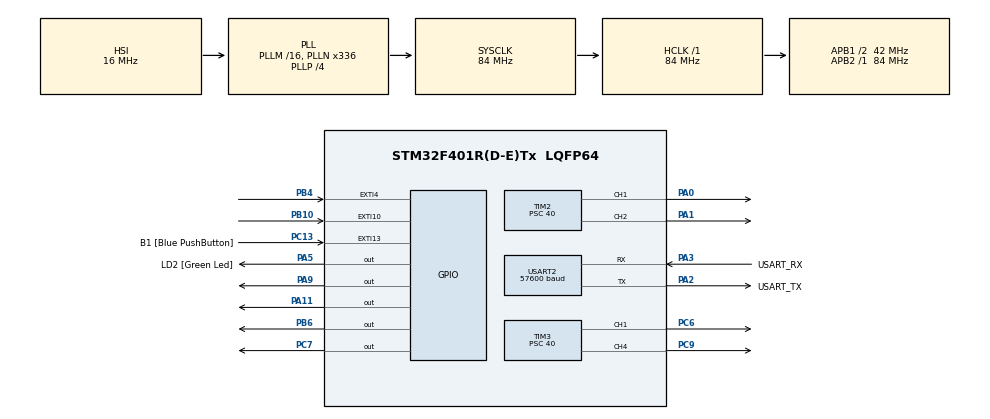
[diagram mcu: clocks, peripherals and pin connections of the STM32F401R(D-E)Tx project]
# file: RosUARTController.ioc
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Dma.Request0=USART2_RX
Dma.Request1=USART2_TX
Dma.USART2_RX.0.Direction=DMA_PERIPH_TO_MEMORY
Dma.USART2_RX.0.FIFOMode=DMA_FIFOMODE_DISABLE
Dma.USART2_RX.0.Instance=DMA1_Stream5
Dma.USART2_RX.0.MemDataAlignment=DMA_MDATAALIGN_BYTE
Dma.USART2_RX.0.MemInc=DMA_MINC_ENABLE
Dma.USART2_RX.0.Mode=DMA_NORMAL
Dma.USART2_RX.0.PeriphDataAlignment=DMA_PDATAALIGN_BYTE
Dma.USART2_RX.0.PeriphInc=DMA_PINC_DISABLE
Dma.USART2_RX.0.Priority=DMA_PRIORITY_HIGH
Dma.USART2_TX.1.Direction=DMA_MEMORY_TO_PERIPH
Dma.USART2_TX.1.FIFOMode=DMA_FIFOMODE_DISABLE
Dma.USART2_TX.1.Instance=DMA1_Stream6
Dma.USART2_TX.1.MemDataAlignment=DMA_MDATAALIGN_BYTE
Dma.USART2_TX.1.MemInc=DMA_MINC_ENABLE
Dma.USART2_TX.1.Mode=DMA_NORMAL
Dma.USART2_TX.1.PeriphDataAlignment=DMA_PDATAALIGN_BYTE
Dma.USART2_TX.1.PeriphInc=DMA_PINC_DISABLE
Dma.USART2_TX.1.Priority=DMA_PRIORITY_HIGH
FREERTOS.Tasks01=defaultTask,0,128,StartDefaultTask,Default,NULL
Mcu.Family=STM32F4
Mcu.Name=STM32F401R(D-E)Tx
Mcu.Package=LQFP64
NVIC.DMA1_Stream5_IRQn=true\:5\:0\:false\:false\:true\:true\:false\:true
NVIC.DMA1_Stream6_IRQn=true\:5\:0\:false\:false\:true\:true\:false\:true
NVIC.EXTI15_10_IRQn=true\:5\:0\:false\:false\:true\:true\:true\:true
NVIC.EXTI4_IRQn=true\:5\:0\:false\:false\:true\:true\:true\:true
NVIC.PriorityGroup=NVIC_PRIORITYGROUP_4
NVIC.TIM1_UP_TIM10_IRQn=true\:0\:0\:false\:false\:true\:false\:false\:true
NVIC.TimeBase=TIM1_UP_TIM10_IRQn
NVIC.TimeBaseIP=TIM1
NVIC.USART2_IRQn=true\:5\:0\:false\:false\:true\:true\:true\:true
PA0-WKUP.Signal=S_TIM2_CH1_ETR
PA1.Signal=S_TIM2_CH2
PA11.Signal=GPIO_Output
PA13.GPIO_Label=TMS
PA13.Mode=Serial_Wire
PA13.Signal=SYS_JTMS-SWDIO
PA14.GPIO_Label=TCK
PA14.Mode=Serial_Wire
PA14.Signal=SYS_JTCK-SWCLK
PA2.GPIO_Label=USART_TX
PA2.GPIO_Mode=GPIO_MODE_AF_PP
PA2.GPIO_PuPd=GPIO_NOPULL
PA2.GPIO_Speed=GPIO_SPEED_FREQ_LOW
PA2.Mode=Asynchronous
PA2.Signal=USART2_TX
PA3.GPIO_Label=USART_RX
PA3.GPIO_Mode=GPIO_MODE_AF_PP
PA3.GPIO_PuPd=GPIO_NOPULL
PA3.GPIO_Speed=GPIO_SPEED_FREQ_LOW
PA3.Mode=Asynchronous
PA3.Signal=USART2_RX
PA5.GPIO_Label=LD2 [Green Led]
PA5.GPIO_Mode=GPIO_MODE_OUTPUT_PP
PA5.GPIO_PuPd=GPIO_NOPULL
PA5.GPIO_Speed=GPIO_SPEED_FREQ_LOW
PA5.Signal=GPIO_Output
PA9.Signal=GPIO_Output
PB10.GPIO_ModeDefaultEXTI=GPIO_MODE_IT_RISING_FALLING
PB10.Signal=GPXTI10
PB3.GPIO_Label=SWO
PB3.Signal=SYS_JTDO-SWO
PB4.GPIO_ModeDefaultEXTI=GPIO_MODE_IT_RISING_FALLING
PB4.Signal=GPXTI4
PB6.Signal=GPIO_Output
PC13-ANTI_TAMP.GPIO_Label=B1 [Blue PushButton]
PC13-ANTI_TAMP.GPIO_ModeDefaultEXTI=GPIO_MODE_IT_FALLING
PC13-ANTI_TAMP.GPIO_PuPd=GPIO_NOPULL
PC13-ANTI_TAMP.Signal=GPXTI13
PC14-OSC32_IN.Mode=LSE-External-Oscillator
PC14-OSC32_IN.Signal=RCC_OSC32_IN
PC15-OSC32_OUT.Mode=LSE-External-Oscillator
PC15-OSC32_OUT.Signal=RCC_OSC32_OUT
PC6.Signal=S_TIM3_CH1
PC7.Signal=GPIO_Output
PC9.Signal=S_TIM3_CH4
PH0\ -\ OSC_IN.Mode=HSE-External-Oscillator
PH0\ -\ OSC_IN.Signal=RCC_OSC_IN
PH1\ -\ OSC_OUT.Mode=HSE-External-Oscillator
PH1\ -\ OSC_OUT.Signal=RCC_OSC_OUT
ProjectManager.HeapSize=0x200
ProjectManager.StackSize=0x400
ProjectManager.TargetToolchain=STM32CubeIDE
RCC.48MHZClocksFreq_Value=48000000
RCC.AHBFreq_Value=84000000
RCC.APB1CLKDivider=RCC_HCLK_DIV2
RCC.APB1Freq_Value=42000000
RCC.APB1TimFreq_Value=84000000
RCC.APB2Freq_Value=84000000
RCC.APB2TimFreq_Value=84000000
RCC.CortexFreq_Value=84000000
RCC.HCLKFreq_Value=84000000
RCC.HSE_VALUE=8000000
RCC.HSI_VALUE=16000000
RCC.PLLN=336
RCC.PLLP=RCC_PLLP_DIV4
RCC.PLLQ=7
RCC.SYSCLKFreq_VALUE=84000000
RCC.SYSCLKSource=RCC_SYSCLKSOURCE_PLLCLK
RCC.VCOOutputFreq_Value=336000000
SH.S_TIM2_CH1_ETR.0=TIM2_CH1,PWM Generation1 CH1
SH.S_TIM2_CH2.0=TIM2_CH2,PWM Generation2 CH2
SH.S_TIM3_CH1.0=TIM3_CH1,PWM Generation1 CH1
SH.S_TIM3_CH4.0=TIM3_CH4,PWM Generation4 CH4
TIM2.Channel-PWM\ Generation1\ CH1=TIM_CHANNEL_1
TIM2.Channel-PWM\ Generation2\ CH2=TIM_CHANNEL_2
TIM2.Period=256
TIM2.Prescaler=40
TIM3.Channel-PWM\ Generation1\ CH1=TIM_CHANNEL_1
TIM3.Channel-PWM\ Generation4\ CH4=TIM_CHANNEL_4
TIM3.Period=256
TIM3.Prescaler=40
USART2.BaudRate=57600
USART2.VirtualMode=VM_ASYNC
VP_FREERTOS_VS_CMSIS_V1.Mode=CMSIS_V1
VP_SYS_VS_tim1.Mode=TIM1
VP_TIM2_VS_ClockSourceINT.Mode=Internal
VP_TIM3_VS_ClockSourceINT.Mode=Internal
board=NUCLEO-F401RE

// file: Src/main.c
/* USER CODE BEGIN Header */
/**
  ******************************************************************************
  * @file           : main.c
  * @brief          : Main program body
  ******************************************************************************
  * @attention
  *
  * <h2><center>&copy; Copyright (c) 2019 STMicroelectronics.
  * All rights reserved.</center></h2>
  *
  * This software component is licensed by ST under BSD 3-Clause license,
  * the "License"; You may not use this file except in compliance with the
  * License. You may obtain a copy of the License at:
  *                        opensource.org/licenses/BSD-3-Clause
  *
  ******************************************************************************
  */
/* USER CODE END Header */

#include "main.h"
#include "cmsis_os.h"

TIM_HandleTypeDef htim2;
TIM_HandleTypeDef htim3;

UART_HandleTypeDef huart2;
DMA_HandleTypeDef hdma_usart2_rx;
DMA_HandleTypeDef hdma_usart2_tx;

osThreadId defaultTaskHandle;

void SystemClock_Config(void);
static void MX_GPIO_Init(void);
static void MX_DMA_Init(void);
static void MX_USART2_UART_Init(void);
static void MX_TIM2_Init(void);
static void MX_TIM3_Init(void);
void StartDefaultTask(void const * argument);

int main(void)
{

  /* MCU Configuration--------------------------------------------------------*/

  /* Reset of all peripherals, Initializes the Flash interface and the Systick. */
  HAL_Init();

  /* Configure the system clock */
  SystemClock_Config();

  /* Initialize all configured peripherals */
  MX_GPIO_Init();
  MX_DMA_Init();
  MX_USART2_UART_Init();
  MX_TIM2_Init();
  MX_TIM3_Init();
  /* USER CODE BEGIN 2 */
    setup(&huart2, &htim2, &htim3);
  /* USER CODE END 2 */

  /* Create the thread(s) */
  /* definition and creation of defaultTask */
  osThreadDef(defaultTask, StartDefaultTask, osPriorityNormal, 0, 128);
  defaultTaskHandle = osThreadCreate(osThread(defaultTask), NULL);

  /* Start scheduler */
  osKernelStart();

  /* We should never get here as control is now taken by the scheduler */

  /* Infinite loop */
  while (1)
  {

  }
}

void SystemClock_Config(void)
{
  RCC_OscInitTypeDef RCC_OscInitStruct = {0};
  RCC_ClkInitTypeDef RCC_ClkInitStruct = {0};

  /** Configure the main internal regulator output voltage
  */
  __HAL_RCC_PWR_CLK_ENABLE();
  __HAL_PWR_VOLTAGESCALING_CONFIG(PWR_REGULATOR_VOLTAGE_SCALE2);
  /** Initializes the CPU, AHB and APB busses clocks
  */
  RCC_OscInitStruct.OscillatorType = RCC_OSCILLATORTYPE_HSI;
  RCC_OscInitStruct.HSIState = RCC_HSI_ON;
  RCC_OscInitStruct.HSICalibrationValue = RCC_HSICALIBRATION_DEFAULT;
  RCC_OscInitStruct.PLL.PLLState = RCC_PLL_ON;
  RCC_OscInitStruct.PLL.PLLSource = RCC_PLLSOURCE_HSI;
  RCC_OscInitStruct.PLL.PLLM = 16;
  RCC_OscInitStruct.PLL.PLLN = 336;
  RCC_OscInitStruct.PLL.PLLP = RCC_PLLP_DIV4;
  RCC_OscInitStruct.PLL.PLLQ = 7;
  if (HAL_RCC_OscConfig(&RCC_OscInitStruct) != HAL_OK)
  {
    Error_Handler();
  }
  /** Initializes the CPU, AHB and APB busses clocks
  */
  RCC_ClkInitStruct.ClockType = RCC_CLOCKTYPE_HCLK|RCC_CLOCKTYPE_SYSCLK
                              |RCC_CLOCKTYPE_PCLK1|RCC_CLOCKTYPE_PCLK2;
  RCC_ClkInitStruct.SYSCLKSource = RCC_SYSCLKSOURCE_PLLCLK;
  RCC_ClkInitStruct.AHBCLKDivider = RCC_SYSCLK_DIV1;
  RCC_ClkInitStruct.APB1CLKDivider = RCC_HCLK_DIV2;
  RCC_ClkInitStruct.APB2CLKDivider = RCC_HCLK_DIV1;

  if (HAL_RCC_ClockConfig(&RCC_ClkInitStruct, FLASH_LATENCY_2) != HAL_OK)
  {
    Error_Handler();
  }
}

static void MX_TIM2_Init(void)
{

  TIM_ClockConfigTypeDef sClockSourceConfig = {0};
  TIM_MasterConfigTypeDef sMasterConfig = {0};
  TIM_OC_InitTypeDef sConfigOC = {0};

  htim2.Instance = TIM2;
  htim2.Init.Prescaler = 40;
  htim2.Init.CounterMode = TIM_COUNTERMODE_UP;
  htim2.Init.Period = 256;
  htim2.Init.ClockDivision = TIM_CLOCKDIVISION_DIV1;
  htim2.Init.AutoReloadPreload = TIM_AUTORELOAD_PRELOAD_DISABLE;
  if (HAL_TIM_Base_Init(&htim2) != HAL_OK)
  {
    Error_Handler();
  }
  sClockSourceConfig.ClockSource = TIM_CLOCKSOURCE_INTERNAL;
  if (HAL_TIM_ConfigClockSource(&htim2, &sClockSourceConfig) != HAL_OK)
  {
    Error_Handler();
  }
  if (HAL_TIM_PWM_Init(&htim2) != HAL_OK)
  {
    Error_Handler();
  }
  sMasterConfig.MasterOutputTrigger = TIM_TRGO_RESET;
  sMasterConfig.MasterSlaveMode = TIM_MASTERSLAVEMODE_DISABLE;
  if (HAL_TIMEx_MasterConfigSynchronization(&htim2, &sMasterConfig) != HAL_OK)
  {
    Error_Handler();
  }
  sConfigOC.OCMode = TIM_OCMODE_PWM1;
  sConfigOC.Pulse = 0;
  sConfigOC.OCPolarity = TIM_OCPOLARITY_HIGH;
  sConfigOC.OCFastMode = TIM_OCFAST_DISABLE;
  if (HAL_TIM_PWM_ConfigChannel(&htim2, &sConfigOC, TIM_CHANNEL_1) != HAL_OK)
  {
    Error_Handler();
  }
  if (HAL_TIM_PWM_ConfigChannel(&htim2, &sConfigOC, TIM_CHANNEL_2) != HAL_OK)
  {
    Error_Handler();
  }
  HAL_TIM_MspPostInit(&htim2);

}

static void MX_TIM3_Init(void)
{

  TIM_ClockConfigTypeDef sClockSourceConfig = {0};
  TIM_MasterConfigTypeDef sMasterConfig = {0};
  TIM_OC_InitTypeDef sConfigOC = {0};

  htim3.Instance = TIM3;
  htim3.Init.Prescaler = 40;
  htim3.Init.CounterMode = TIM_COUNTERMODE_UP;
  htim3.Init.Period = 256;
  htim3.Init.ClockDivision = TIM_CLOCKDIVISION_DIV1;
  htim3.Init.AutoReloadPreload = TIM_AUTORELOAD_PRELOAD_DISABLE;
  if (HAL_TIM_Base_Init(&htim3) != HAL_OK)
  {
    Error_Handler();
  }
  sClockSourceConfig.ClockSource = TIM_CLOCKSOURCE_INTERNAL;
  if (HAL_TIM_ConfigClockSource(&htim3, &sClockSourceConfig) != HAL_OK)
  {
    Error_Handler();
  }
  if (HAL_TIM_PWM_Init(&htim3) != HAL_OK)
  {
    Error_Handler();
  }
  sMasterConfig.MasterOutputTrigger = TIM_TRGO_RESET;
  sMasterConfig.MasterSlaveMode = TIM_MASTERSLAVEMODE_DISABLE;
  if (HAL_TIMEx_MasterConfigSynchronization(&htim3, &sMasterConfig) != HAL_OK)
  {
    Error_Handler();
  }
  sConfigOC.OCMode = TIM_OCMODE_PWM1;
  sConfigOC.Pulse = 0;
  sConfigOC.OCPolarity = TIM_OCPOLARITY_HIGH;
  sConfigOC.OCFastMode = TIM_OCFAST_DISABLE;
  if (HAL_TIM_PWM_ConfigChannel(&htim3, &sConfigOC, TIM_CHANNEL_1) != HAL_OK)
  {
    Error_Handler();
  }
  if (HAL_TIM_PWM_ConfigChannel(&htim3, &sConfigOC, TIM_CHANNEL_4) != HAL_OK)
  {
    Error_Handler();
  }
  HAL_TIM_MspPostInit(&htim3);

}

static void MX_USART2_UART_Init(void)
{

  huart2.Instance = USART2;
  huart2.Init.BaudRate = 57600;
  huart2.Init.WordLength = UART_WORDLENGTH_8B;
  huart2.Init.StopBits = UART_STOPBITS_1;
  huart2.Init.Parity = UART_PARITY_NONE;
  huart2.Init.Mode = UART_MODE_TX_RX;
  huart2.Init.HwFlowCtl = UART_HWCONTROL_NONE;
  huart2.Init.OverSampling = UART_OVERSAMPLING_16;
  if (HAL_UART_Init(&huart2) != HAL_OK)
  {
    Error_Handler();
  }

}

static void MX_DMA_Init(void)
{

  /* DMA controller clock enable */
  __HAL_RCC_DMA1_CLK_ENABLE();

  /* DMA interrupt init */
  /* DMA1_Stream5_IRQn interrupt configuration */
  HAL_NVIC_SetPriority(DMA1_Stream5_IRQn, 5, 0);
  HAL_NVIC_EnableIRQ(DMA1_Stream5_IRQn);
  /* DMA1_Stream6_IRQn interrupt configuration */
  HAL_NVIC_SetPriority(DMA1_Stream6_IRQn, 5, 0);
  HAL_NVIC_EnableIRQ(DMA1_Stream6_IRQn);

}

static void MX_GPIO_Init(void)
{
  GPIO_InitTypeDef GPIO_InitStruct = {0};

  /* GPIO Ports Clock Enable */
  __HAL_RCC_GPIOC_CLK_ENABLE();
  __HAL_RCC_GPIOH_CLK_ENABLE();
  __HAL_RCC_GPIOA_CLK_ENABLE();
  __HAL_RCC_GPIOB_CLK_ENABLE();

  /*Configure GPIO pin Output Level */
  HAL_GPIO_WritePin(GPIOA, LD2_Pin|GPIO_PIN_9|GPIO_PIN_11, GPIO_PIN_RESET);

  /*Configure GPIO pin Output Level */
  HAL_GPIO_WritePin(GPIOC, GPIO_PIN_7, GPIO_PIN_RESET);

  /*Configure GPIO pin Output Level */
  HAL_GPIO_WritePin(GPIOB, GPIO_PIN_6, GPIO_PIN_RESET);

  /*Configure GPIO pin : B1_Pin */
  GPIO_InitStruct.Pin = B1_Pin;
  GPIO_InitStruct.Mode = GPIO_MODE_IT_FALLING;
  GPIO_InitStruct.Pull = GPIO_NOPULL;
  HAL_GPIO_Init(B1_GPIO_Port, &GPIO_InitStruct);

  /*Configure GPIO pins : LD2_Pin PA9 PA11 */
  GPIO_InitStruct.Pin = LD2_Pin|GPIO_PIN_9|GPIO_PIN_11;
  GPIO_InitStruct.Mode = GPIO_MODE_OUTPUT_PP;
  GPIO_InitStruct.Pull = GPIO_NOPULL;
  GPIO_InitStruct.Speed = GPIO_SPEED_FREQ_LOW;
  HAL_GPIO_Init(GPIOA, &GPIO_InitStruct);

  /*Configure GPIO pins : PB10 PB4 */
  GPIO_InitStruct.Pin = GPIO_PIN_10|GPIO_PIN_4;
  GPIO_InitStruct.Mode = GPIO_MODE_IT_RISING_FALLING;
  GPIO_InitStruct.Pull = GPIO_NOPULL;
  HAL_GPIO_Init(GPIOB, &GPIO_InitStruct);

  /*Configure GPIO pin : PC7 */
  GPIO_InitStruct.Pin = GPIO_PIN_7;
  GPIO_InitStruct.Mode = GPIO_MODE_OUTPUT_PP;
  GPIO_InitStruct.Pull = GPIO_NOPULL;
  GPIO_InitStruct.Speed = GPIO_SPEED_FREQ_LOW;
  HAL_GPIO_Init(GPIOC, &GPIO_InitStruct);

  /*Configure GPIO pin : PB6 */
  GPIO_InitStruct.Pin = GPIO_PIN_6;
  GPIO_InitStruct.Mode = GPIO_MODE_OUTPUT_PP;
  GPIO_InitStruct.Pull = GPIO_NOPULL;
  GPIO_InitStruct.Speed = GPIO_SPEED_FREQ_LOW;
  HAL_GPIO_Init(GPIOB, &GPIO_InitStruct);

  /* EXTI interrupt init*/
  HAL_NVIC_SetPriority(EXTI4_IRQn, 5, 0);
  HAL_NVIC_EnableIRQ(EXTI4_IRQn);

  HAL_NVIC_SetPriority(EXTI15_10_IRQn, 5, 0);
  HAL_NVIC_EnableIRQ(EXTI15_10_IRQn);

}

void StartDefaultTask(void const * argument)
{

  /* USER CODE BEGIN 5 */
  /* Infinite loop */
//	  HAL_GPIO_WritePin(GPIOA, GPIO_PIN_9, 1);
//	  HAL_GPIO_WritePin(GPIOC, GPIO_PIN_7, 1);
//	  HAL_TIM_PWM_Start(&htim2, TIM_CHANNEL_1);
//	  __HAL_TIM_SetCompare(&htim2, TIM_CHANNEL_1, 128);
  for(;;)
  {

    osDelay(1);
  }
  /* USER CODE END 5 */
}

void HAL_TIM_PeriodElapsedCallback(TIM_HandleTypeDef *htim)
{
  if (htim->Instance == TIM1) {
    HAL_IncTick();
  }
}

void Error_Handler(void)
{
}

/************************ (C) COPYRIGHT STMicroelectronics *****END OF FILE****/
